# CortexM33 register map
CPU: CM33 r1p0, little endian, MPU, FPU, DSP, VTOR, 4 interrupt priority bits, 52 interrupts, 8 SAU regions
Registers are read-write, reset 0x0 unless marked. A register's access mark holds for its fields unless they carry their own. Offsets are from the block's base; [hi:lo] are bit positions; lines under a group give offsets from that group; {n}, {i} and the like mark numbered series; 'fields as' and 'values as' point back to an identical list.

## PPB (part 2 of 2) — TEAL registers accessible through the debug interface
Base 0xE0000000
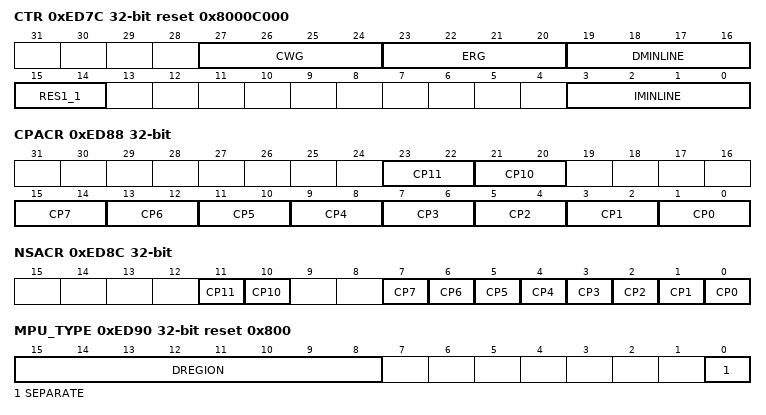
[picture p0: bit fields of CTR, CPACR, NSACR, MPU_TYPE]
0xED7C CTR ro reset 0x8000C000 — Provides information about the architecture of the caches. CTR is RES0 if CLIDR is zero.
  [27:24] CWG — Log2 of the number of words of the maximum size of memory that can be overwritten as a result of the eviction of a cache entry that has had a memory location in it modified
  [23:20] ERG — Log2 of the number of words of the maximum size of the reservation granule that has been implemented for the Load-Exclusive and Store-Exclusive instructions
  [19:16] DMINLINE — Log2 of the number of words in the smallest cache line of all the data caches and unified caches that are controlled by the PE
  [15:14] RES1_1 — Reserved, RES1
  [3:0] IMINLINE — Log2 of the number of words in the smallest cache line of all the instruction caches that are controlled by the PE
0xED88 CPACR — Specifies the access privileges for coprocessors and the FP Extension
  [23:22] CP11 — The value in this field is ignored. If the implementation does not include the FP Extension, this field is RAZ/WI. If the value of this bit is not programmed to the same value as the CP10 field, then the value is UNKNOWN
  [21:20] CP10 — Defines the access rights for the floating-point functionality
  [2n+1:2n] CP{n} (n=0..7) — Controls access privileges for coprocessor {n}
0xED8C NSACR — Defines the Non-secure access permissions for both the FP Extension and coprocessors CP0 to CP7
  [11] CP11 — Enables Non-secure access to the Floating-point Extension
  [10] CP10 — Enables Non-secure access to the Floating-point Extension
  [n] CP{n} (n=0..7) — Enables Non-secure access to coprocessor CP{n}
0xED90 MPU_TYPE ro reset 0x800 — The MPU Type Register indicates how many regions the MPU `FTSSS supports
  [15:8] DREGION — Number of regions supported by the MPU
  [0] SEPARATE — Indicates support for separate instructions and data address regions
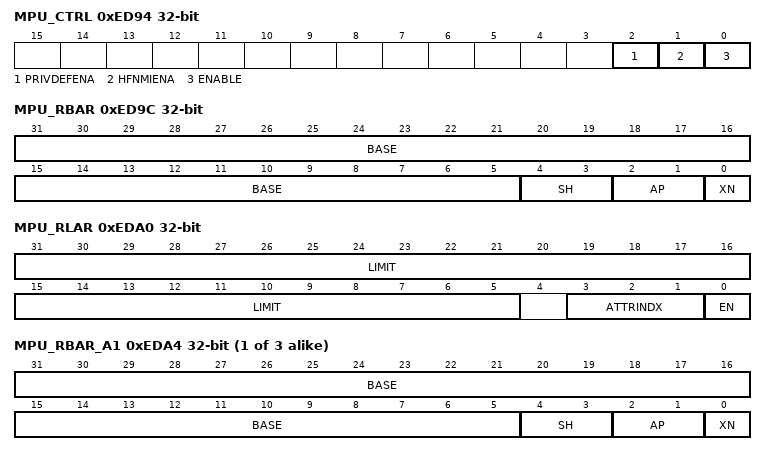
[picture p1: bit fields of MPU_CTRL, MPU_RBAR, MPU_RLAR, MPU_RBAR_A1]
0xED94 MPU_CTRL — Enables the MPU and, when the MPU is enabled, controls whether the default memory map is enabled as a background region for privileged accesses, and whether the MPU is enabled for HardFaults, NMIs, and exception handlers when FAULTMASK is set to 1
  [2] PRIVDEFENA — Controls whether the default memory map is enabled for privileged software
  [1] HFNMIENA — Controls whether handlers executing with priority less than 0 access memory with the MPU enabled or disabled. This applies to HardFaults, NMIs, and exception handlers when FAULTMASK is set to 1
  [0] ENABLE — Enables the MPU
0xED98 MPU_RNR — Selects the region currently accessed by MPU_RBAR and MPU_RLAR
  [2:0] REGION — Indicates the memory region accessed by MPU_RBAR and MPU_RLAR
0xED9C MPU_RBAR — Provides indirect read and write access to the base address of the currently selected MPU region `FTSSS
  [31:5] BASE — Contains bits [31:5] of the lower inclusive limit of the selected MPU memory region. This value is zero extended to provide the base address to be checked against
  [4:3] SH — Defines the Shareability domain of this region for Normal memory
  [2:1] AP — Defines the access permissions for this region
  [0] XN — Defines whether code can be executed from this region
0xEDA0 MPU_RLAR — Provides indirect read and write access to the limit address of the currently selected MPU region `FTSSS
  [31:5] LIMIT — Contains bits [31:5] of the upper inclusive limit of the selected MPU memory region. This value is postfixed with 0x1F to provide the limit address to be checked against
  [3:1] ATTRINDX — Associates a set of attributes in the MPU_MAIR0 and MPU_MAIR1 fields
  [0] EN — Region enable
{0xED9C+8i} MPU_RBAR_A{i} (i=1..3) — Provides indirect read and write access to the base address of the MPU region selected by MPU_RNR[7:2]:({i}[1:0]) `FTSSS
  fields as MPU_RBAR
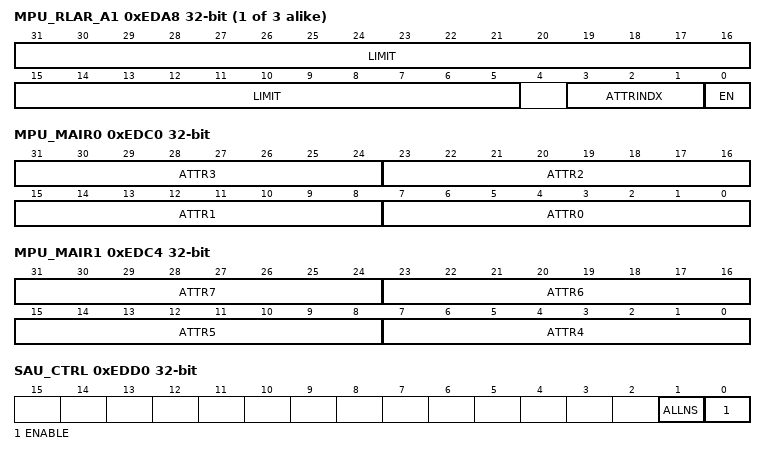
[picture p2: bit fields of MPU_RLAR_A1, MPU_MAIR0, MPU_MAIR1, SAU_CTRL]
{0xEDA0+8i} MPU_RLAR_A{i} (i=1..3) — Provides indirect read and write access to the limit address of the currently selected MPU region selected by MPU_RNR[7:2]:({i}[1:0]) `FTSSS
  fields as MPU_RLAR
0xEDC0 MPU_MAIR0 — Along with MPU_MAIR1, provides the memory attribute encodings corresponding to the AttrIndex values
  [8n+7:8n] ATTR{n} (n=0..3) — Memory attribute encoding for MPU regions with an AttrIndex of {n}
0xEDC4 MPU_MAIR1 — Along with MPU_MAIR0, provides the memory attribute encodings corresponding to the AttrIndex values
  [8n-25:8n-32] ATTR{n} (n=4..7) — Memory attribute encoding for MPU regions with an AttrIndex of {n}
0xEDD0 SAU_CTRL — Allows enabling of the Security Attribution Unit
  [1] ALLNS — When SAU_CTRL.ENABLE is 0 this bit controls if the memory is marked as Non-secure or Secure
  [0] ENABLE — Enables the SAU
0xEDD4 SAU_TYPE ro reset 0x8 — Indicates the number of regions implemented by the Security Attribution Unit
  [7:0] SREGION — The number of implemented SAU regions
0xEDD8 SAU_RNR — Selects the region currently accessed by SAU_RBAR and SAU_RLAR
  [7:0] REGION — Indicates the SAU region accessed by SAU_RBAR and SAU_RLAR
0xEDDC SAU_RBAR — Provides indirect read and write access to the base address of the currently selected SAU region
  [31:5] BADDR — Holds bits [31:5] of the base address for the selected SAU region
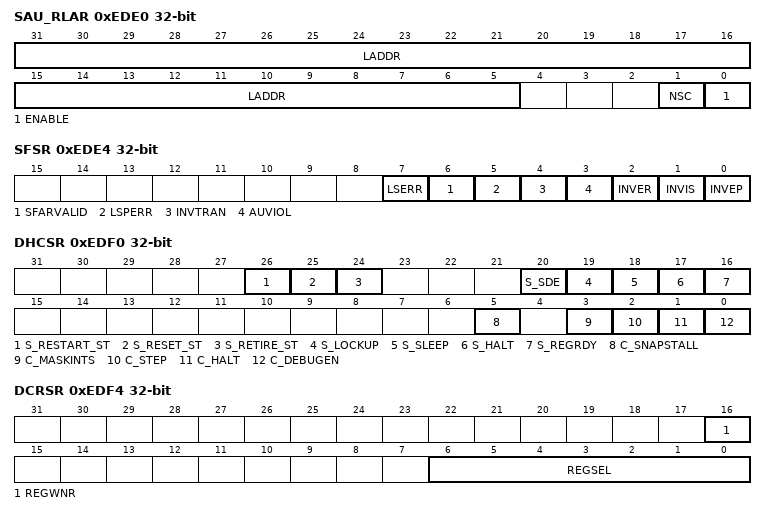
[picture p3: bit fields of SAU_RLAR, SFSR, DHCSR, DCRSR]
0xEDE0 SAU_RLAR — Provides indirect read and write access to the limit address of the currently selected SAU region
  [31:5] LADDR — Holds bits [31:5] of the limit address for the selected SAU region
  [1] NSC — Controls whether Non-secure state is permitted to execute an SG instruction from this region
  [0] ENABLE — SAU region enable
0xEDE4 SFSR — Provides information about any security related faults
  [7] LSERR — Sticky flag indicating that an error occurred during lazy state activation or deactivation
  [6] SFARVALID — This bit is set when the SFAR register contains a valid value. As with similar fields, such as BFSR.BFARVALID and MMFSR.MMARVALID, this bit can be cleared by other exceptions, such as BusFault
  [5] LSPERR — Stick flag indicating that an SAU or IDAU violation occurred during the lazy preservation of floating-point state
  [4] INVTRAN — Sticky flag indicating that an exception was raised due to a branch that was not flagged as being domain crossing causing a transition from Secure to Non-secure memory
  [3] AUVIOL — Sticky flag indicating that an attempt was made to access parts of the address space that are marked as Secure with NS-Req for the transaction set to Non-secure. This bit is not set if the violation occurred during lazy state preservation. See LSPERR
  [2] INVER — This can be caused by EXC_RETURN.DCRS being set to 0 when returning from an exception in the Non-secure state, or by EXC_RETURN.ES being set to 1 when returning from an exception in the Non-secure state
  [1] INVIS — This bit is set if the integrity signature in an exception stack frame is found to be invalid during the unstacking operation
  [0] INVEP — This bit is set if a function call from the Non-secure state or exception targets a non-SG instruction in the Secure state. This bit is also set if the target address is a SG instruction, but there is no matching SAU/IDAU region with the NSC flag set
0xEDE8 SFAR — Shows the address of the memory location that caused a Security violation
  [31:0] ADDRESS — The address of an access that caused a attribution unit violation. This field is only valid when SFSR.SFARVALID is set. This allows the actual flip flops associated with this register to be shared with other fault address registers. If an implementation chooses to share the storage in this way, care must be taken to not leak Secure address information to the Non-secure state. One way of achieving this is to share the SFAR register with the MMFAR_S register, which is not accessible to the Non-secure state
0xEDF0 DHCSR access per field — Controls halting debug
  [26] S_RESTART_ST ro — Indicates the PE has processed a request to clear DHCSR.C_HALT to 0. That is, either a write to DHCSR that clears DHCSR.C_HALT from 1 to 0, or an External Restart Request
  [25] S_RESET_ST ro — Indicates whether the PE has been reset since the last read of the DHCSR
  [24] S_RETIRE_ST ro — Set to 1 every time the PE retires one of more instructions
  [20] S_SDE ro — Indicates whether Secure invasive debug is allowed
  [19] S_LOCKUP ro — Indicates whether the PE is in Lockup state
  [18] S_SLEEP ro — Indicates whether the PE is sleeping
  [17] S_HALT ro — Indicates whether the PE is in Debug state
  [16] S_REGRDY ro — Handshake flag to transfers through the DCRDR
  [5] C_SNAPSTALL rw — Allow imprecise entry to Debug state
  [3] C_MASKINTS rw — When debug is enabled, the debugger can write to this bit to mask PendSV, SysTick and external configurable interrupts
  [2] C_STEP rw — Enable single instruction step
  [1] C_HALT rw — PE enter Debug state halt request
  [0] C_DEBUGEN rw — Enable Halting debug
0xEDF4 DCRSR — With the DCRDR, provides debug access to the general-purpose registers, special-purpose registers, and the FP extension registers. A write to the DCRSR specifies the register to transfer, whether the transfer is a read or write, and starts the transfer
  [16] REGWNR — Specifies the access type for the transfer
  [6:0] REGSEL — Specifies the general-purpose register, special-purpose register, or FP register to transfer
    {v}=R{v} (v=0..12); 13=SP (stack pointer); 14=LR (link register); 15=DebugReturnAddress; 16=XPSR (R) / EAPSR (W); 17=MSP (main stack pointer, SP_main); 18=MSP (process stack pointer, SP_process); 20=Current state (CONTROL | FAULTMASK | BASEPRI | PRIMASK ); 24=MSP_NS (non-secure main stack pointer); 25=PSP_NS (non-secure process stack pointer); 25=PSP_NS (non-secure process stack pointer); 26=MSP_S (secure main stack pointer); 27=PSP_S (secure process stack pointer); 28=MSPLIM_S (secure main stack limit); 29=PSPLIM_S (secure process stack limit); 30=MSPLIM_NS (non-secure main stack limit); 31=PSPLIM_NS (non-secure process stack limit); 33=FPSCR; 34=Secure state (CONTROL_S | FAULTMASK_S | BASEPRI_S | PRIMASK_S); 35=Non-secure state (CONTROL_NS | FAULTMASK_NS | BASEPRI_NS | PRIMASK_NS); 36=VPR; {v}=S{v-64} (FP register) (v=64..95)
0xEDF8 DCRDR — With the DCRSR, provides debug access to the general-purpose registers, special-purpose registers, and the FP Extension registers. If the Main Extension is implemented, it can also be used for message passing between an external debugger and a debug agent running on the PE
  [31:0] DBGTMP — Provides debug access for reading and writing the general-purpose registers, special-purpose registers, and Floating-point Extension registers
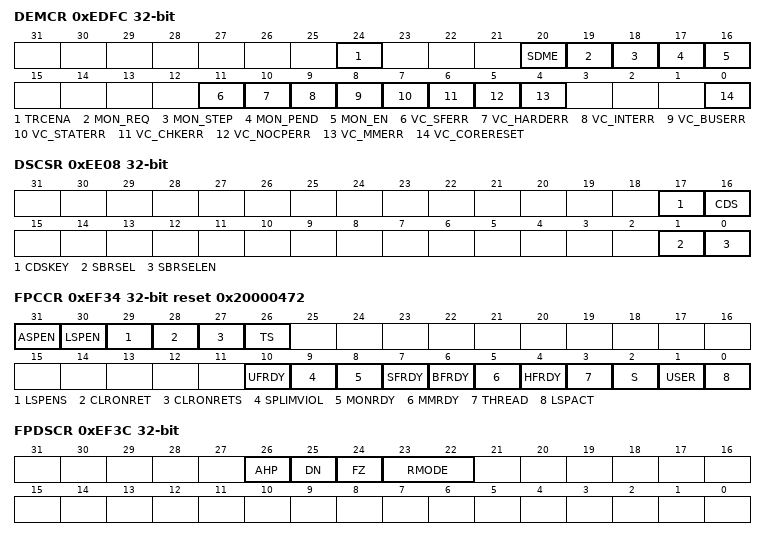
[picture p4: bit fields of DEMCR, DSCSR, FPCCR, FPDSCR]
0xEDFC DEMCR access per field — Manages vector catch behavior and DebugMonitor handling when debugging
  [24] TRCENA rw — Global enable for all DWT and ITM features
  [20] SDME ro — Indicates whether the DebugMonitor targets the Secure or the Non-secure state and whether debug events are allowed in Secure state
  [19] MON_REQ rw — DebugMonitor semaphore bit
  [18] MON_STEP rw — Enable DebugMonitor stepping
  [17] MON_PEND rw — Sets or clears the pending state of the DebugMonitor exception
  [16] MON_EN rw — Enable the DebugMonitor exception
  [11] VC_SFERR rw — SecureFault exception halting debug vector catch enable
  [10] VC_HARDERR rw — HardFault exception halting debug vector catch enable
  [9] VC_INTERR rw — Enable halting debug vector catch for faults during exception entry and return
  [8] VC_BUSERR rw — BusFault exception halting debug vector catch enable
  [7] VC_STATERR rw — Enable halting debug trap on a UsageFault exception caused by a state information error, for example an Undefined Instruction exception
  [6] VC_CHKERR rw — Enable halting debug trap on a UsageFault exception caused by a checking error, for example an alignment check error
  [5] VC_NOCPERR rw — Enable halting debug trap on a UsageFault caused by an access to a coprocessor
  [4] VC_MMERR rw — Enable halting debug trap on a MemManage exception
  [0] VC_CORERESET rw — Enable Reset Vector Catch. This causes a warm reset to halt a running system
0xEE08 DSCSR — Provides control and status information for Secure debug
  [17] CDSKEY — Writes to the CDS bit are ignored unless CDSKEY is concurrently written to zero
  [16] CDS — This field indicates the current Security state of the processor
  [1] SBRSEL — If SBRSELEN is 1 this bit selects whether the Non-secure or the Secure version of the memory-mapped Banked registers are accessible to the debugger
  [0] SBRSELEN — Controls whether the SBRSEL field or the current Security state of the processor selects which version of the memory-mapped Banked registers are accessed to the debugger
0xEF00 STIR — Provides a mechanism for software to generate an interrupt
  [8:0] INTID — Indicates the interrupt to be pended. The value written is (ExceptionNumber - 16)
0xEF34 FPCCR reset 0x20000472 — Holds control data for the Floating-point extension
  [31] ASPEN — When this bit is set to 1, execution of a floating-point instruction sets the CONTROL.FPCA bit to 1
  [30] LSPEN — Enables lazy context save of floating-point state
  [29] LSPENS — This bit controls whether the LSPEN bit is writeable from the Non-secure state
  [28] CLRONRET — Clear floating-point caller saved registers on exception return
  [27] CLRONRETS — This bit controls whether the CLRONRET bit is writeable from the Non-secure state
  [26] TS — Treat floating-point registers as Secure enable
  [10] UFRDY — Indicates whether the software executing when the PE allocated the floating-point stack frame was able to set the UsageFault exception to pending
  [9] SPLIMVIOL — This bit is banked between the Security states and indicates whether the floating-point context violates the stack pointer limit that was active when lazy state preservation was activated. SPLIMVIOL modifies the lazy floating-point state preservation behavior
  [8] MONRDY — Indicates whether the software executing when the PE allocated the floating-point stack frame was able to set the DebugMonitor exception to pending
  [7] SFRDY — Indicates whether the software executing when the PE allocated the floating-point stack frame was able to set the SecureFault exception to pending. This bit is only present in the Secure version of the register, and behaves as RAZ/WI when accessed from the Non-secure state
  [6] BFRDY — Indicates whether the software executing when the PE allocated the floating-point stack frame was able to set the BusFault exception to pending
  [5] MMRDY — Indicates whether the software executing when the PE allocated the floating-point stack frame was able to set the MemManage exception to pending
  [4] HFRDY — Indicates whether the software executing when the PE allocated the floating-point stack frame was able to set the HardFault exception to pending
  [3] THREAD — Indicates the PE mode when it allocated the floating-point stack frame
  [2] S — Security status of the floating-point context. This bit is only present in the Secure version of the register, and behaves as RAZ/WI when accessed from the Non-secure state. This bit is updated whenever lazy state preservation is activated, or when a floating-point instruction is executed
  [1] USER — Indicates the privilege level of the software executing when the PE allocated the floating-point stack frame
  [0] LSPACT — Indicates whether lazy preservation of the floating-point state is active
0xEF38 FPCAR — Holds the location of the unpopulated floating-point register space allocated on an exception stack frame
  [31:3] ADDRESS — The location of the unpopulated floating-point register space allocated on an exception stack frame
0xEF3C FPDSCR — Holds the default values for the floating-point status control data that the PE assigns to the FPSCR when it creates a new floating-point context
  [26] AHP — Default value for FPSCR.AHP
  [25] DN — Default value for FPSCR.DN
  [24] FZ — Default value for FPSCR.FZ
  [23:22] RMODE — Default value for FPSCR.RMode
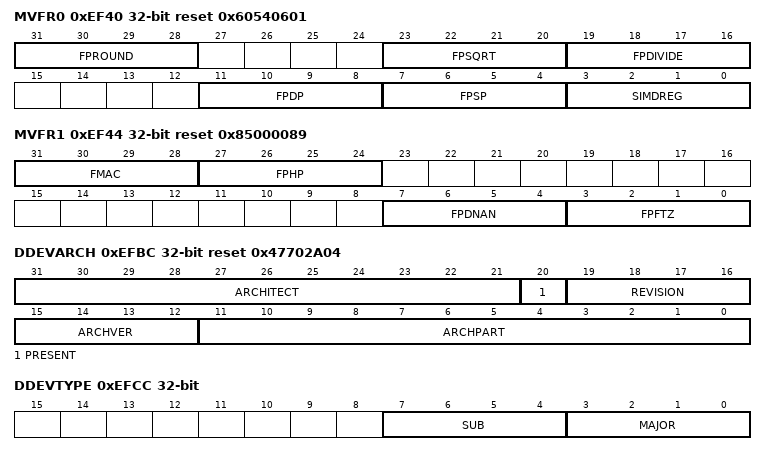
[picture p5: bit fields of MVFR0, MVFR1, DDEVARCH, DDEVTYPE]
0xEF40 MVFR0 ro reset 0x60540601 — Describes the features provided by the Floating-point Extension
  [31:28] FPROUND — Indicates the rounding modes supported by the FP Extension
  [23:20] FPSQRT — Indicates the support for FP square root operations
  [19:16] FPDIVIDE — Indicates the support for FP divide operations
  [11:8] FPDP — Indicates support for FP double-precision operations
  [7:4] FPSP — Indicates support for FP single-precision operations
  [3:0] SIMDREG — Indicates size of FP register file
0xEF44 MVFR1 ro reset 0x85000089 — Describes the features provided by the Floating-point Extension
  [31:28] FMAC — Indicates whether the FP Extension implements the fused multiply accumulate instructions
  [27:24] FPHP — Indicates whether the FP Extension implements half-precision FP conversion instructions
  [7:4] FPDNAN — Indicates whether the FP hardware implementation supports NaN propagation
  [3:0] FPFTZ — Indicates whether subnormals are always flushed-to-zero
0xEF48 MVFR2 ro reset 0x60 — Describes the features provided by the Floating-point Extension
  [7:4] FPMISC — Indicates support for miscellaneous FP features
0xEFBC DDEVARCH ro reset 0x47702A04 — Provides CoreSight discovery information for the SCS
  [31:21] ARCHITECT — Defines the architect of the component. Bits [31:28] are the JEP106 continuation code (JEP106 bank ID, minus 1) and bits [27:21] are the JEP106 ID code.
  [20] PRESENT — Defines that the DEVARCH register is present
  [19:16] REVISION — Defines the architecture revision of the component
  [15:12] ARCHVER — Defines the architecture version of the component
  [11:0] ARCHPART — Defines the architecture of the component
0xEFCC DDEVTYPE ro — Provides CoreSight discovery information for the SCS
  [7:4] SUB — Component sub-type
  [3:0] MAJOR — CoreSight major type
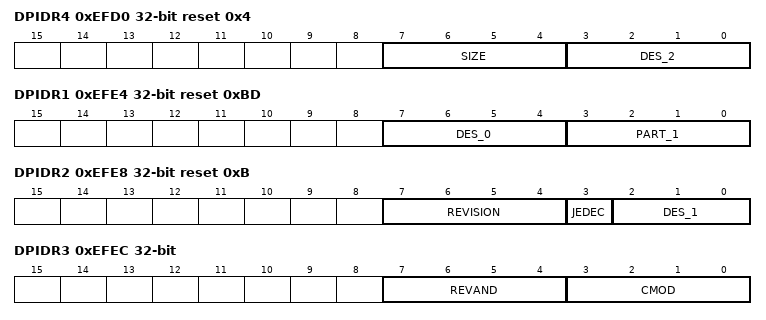
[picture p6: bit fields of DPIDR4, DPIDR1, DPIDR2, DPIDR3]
0xEFD0 DPIDR4 ro reset 0x4 — Provides CoreSight discovery information for the SCS
  [7:4] SIZE — See CoreSight Architecture Specification
  [3:0] DES_2 — See CoreSight Architecture Specification
{0xEFC0+4i} DPIDR{i} (i=5..7) — Provides CoreSight discovery information for the SCS
  [31:0] DPIDR{i}
0xEFE0 DPIDR0 ro reset 0x21 — Provides CoreSight discovery information for the SCS
  [7:0] PART_0 — See CoreSight Architecture Specification
0xEFE4 DPIDR1 ro reset 0xBD — Provides CoreSight discovery information for the SCS
  [7:4] DES_0 — See CoreSight Architecture Specification
  [3:0] PART_1 — See CoreSight Architecture Specification
0xEFE8 DPIDR2 ro reset 0xB — Provides CoreSight discovery information for the SCS
  [7:4] REVISION — See CoreSight Architecture Specification
  [3] JEDEC — See CoreSight Architecture Specification
  [2:0] DES_1 — See CoreSight Architecture Specification
0xEFEC DPIDR3 ro — Provides CoreSight discovery information for the SCS
  [7:4] REVAND — See CoreSight Architecture Specification
  [3:0] CMOD — See CoreSight Architecture Specification
0xEFF0 DCIDR0 ro reset 0xD — Provides CoreSight discovery information for the SCS
  [7:0] PRMBL_0 — See CoreSight Architecture Specification
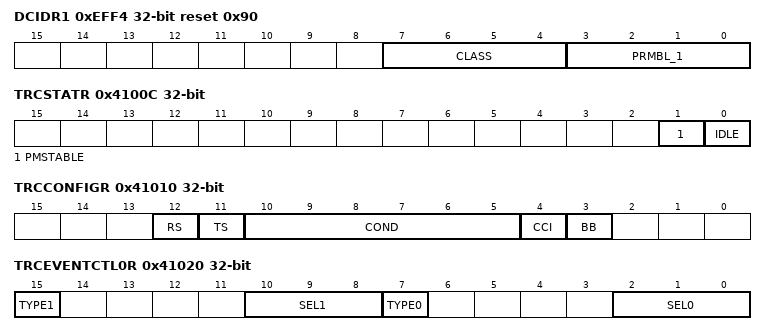
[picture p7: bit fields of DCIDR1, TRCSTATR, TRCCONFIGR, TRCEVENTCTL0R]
0xEFF4 DCIDR1 ro reset 0x90 — Provides CoreSight discovery information for the SCS
  [7:4] CLASS — See CoreSight Architecture Specification
  [3:0] PRMBL_1 — See CoreSight Architecture Specification
0xEFF8 DCIDR2 ro reset 0x5 — Provides CoreSight discovery information for the SCS
  [7:0] PRMBL_2 — See CoreSight Architecture Specification
0xEFFC DCIDR3 ro reset 0xB1 — Provides CoreSight discovery information for the SCS
  [7:0] PRMBL_3 — See CoreSight Architecture Specification
0x41004 TRCPRGCTLR — Programming Control Register
  [0] EN — Trace Unit Enable
0x4100C TRCSTATR ro — The TRCSTATR indicates the ETM-Teal status
  [1] PMSTABLE — Indicates whether the ETM-Teal registers are stable and can be read
  [0] IDLE — Indicates that the trace unit is inactive
0x41010 TRCCONFIGR — The TRCCONFIGR sets the basic tracing options for the trace unit
  [12] RS — Return stack enable
  [11] TS — Global timestamp tracing
  [10:5] COND — Conditional instruction tracing
  [4] CCI — Cycle counting in instruction trace
  [3] BB — Branch broadcast mode
0x41020 TRCEVENTCTL0R — The TRCEVENTCTL0R controls the tracing of events in the trace stream. The events also drive the ETM-Teal external outputs.
  [15] TYPE1 — Selects the resource type for event 1
  [10:8] SEL1 — Selects the resource number, based on the value of TYPE1: When TYPE1 is 0, selects a single selected resource from 0-15 defined by SEL1[2:0]. When TYPE1 is 1, selects a Boolean combined resource pair from 0-7 defined by SEL1[2:0]
  [7] TYPE0 — Selects the resource type for event 0
  [2:0] SEL0 — Selects the resource number, based on the value of TYPE0: When TYPE1 is 0, selects a single selected resource from 0-15 defined by SEL0[2:0]. When TYPE1 is 1, selects a Boolean combined resource pair from 0-7 defined by SEL0[2:0]
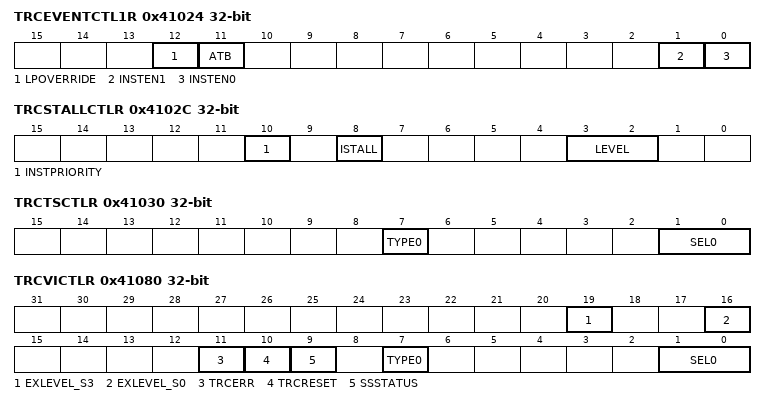
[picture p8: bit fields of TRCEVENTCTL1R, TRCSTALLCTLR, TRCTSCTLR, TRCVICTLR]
0x41024 TRCEVENTCTL1R — The TRCEVENTCTL1R controls how the events selected by TRCEVENTCTL0R behave
  [12] LPOVERRIDE — Low power state behavior override
  [11] ATB — ATB enabled
  [1] INSTEN1 — One bit per event, to enable generation of an event element in the instruction trace stream when the selected event occurs
  [0] INSTEN0 — One bit per event, to enable generation of an event element in the instruction trace stream when the selected event occurs
0x4102C TRCSTALLCTLR access per field — The TRCSTALLCTLR enables ETM-Teal to stall the processor if the ETM-Teal FIFO goes over the programmed level to minimize risk of overflow
  [10] INSTPRIORITY ro — Reserved, RES0
  [8] ISTALL rw — Stall processor based on instruction trace buffer space
  [3:2] LEVEL rw — Threshold at which stalling becomes active. This provides four levels. This level can be varied to optimize the level of invasion caused by stalling, balanced against the risk of a FIFO overflow
0x41030 TRCTSCTLR — The TRCTSCTLR controls the insertion of global timestamps into the trace stream. A timestamp is always inserted into the instruction trace stream
  [7] TYPE0 — Selects the resource type for event 0
  [1:0] SEL0 — Selects the resource number, based on the value of TYPE0: When TYPE1 is 0, selects a single selected resource from 0-15 defined by SEL0[2:0]. When TYPE1 is 1, selects a Boolean combined resource pair from 0-7 defined by SEL0[2:0]
0x41034 TRCSYNCPR ro reset 0xA — The TRCSYNCPR specifies the period of trace synchronization of the trace streams. TRCSYNCPR defines a number of bytes of trace between requests for trace synchronization. This value is always a power of two
  [4:0] PERIOD — Defines the number of bytes of trace between trace synchronization requests as a total of the number of bytes generated by the instruction stream. The number of bytes is 2N where N is the value of this field: - A value of zero disables these periodic trace synchronization requests, but does not disable other trace synchronization requests. - The minimum value that can be programmed, other than zero, is 8, providing a minimum trace synchronization period of 256 bytes. - The maximum value is 20, providing a maximum trace synchronization period of 2^20 bytes
0x41038 TRCCCCTLR — The TRCCCCTLR sets the threshold value for instruction trace cycle counting. The threshold represents the minimum interval between cycle count trace packets
  [11:0] THRESHOLD — Instruction trace cycle count threshold
0x41080 TRCVICTLR — The TRCVICTLR controls instruction trace filtering
  [19] EXLEVEL_S3 — In Secure state, each bit controls whether instruction tracing is enabled for the corresponding exception level
  [16] EXLEVEL_S0 — In Secure state, each bit controls whether instruction tracing is enabled for the corresponding exception level
  [11] TRCERR — Selects whether a system error exception must always be traced
  [10] TRCRESET — Selects whether a reset exception must always be traced
  [9] SSSTATUS — Indicates the current status of the start/stop logic
  [7] TYPE0 — Selects the resource type for event 0
  [1:0] SEL0 — Selects the resource number, based on the value of TYPE0: When TYPE1 is 0, selects a single selected resource from 0-15 defined by SEL0[2:0]. When TYPE1 is 1, selects a Boolean combined resource pair from 0-7 defined by SEL0[2:0]
0x41140 TRCCNTRLDVR0 — The TRCCNTRLDVR defines the reload value for the reduced function counter
  [15:0] VALUE — Defines the reload value for the counter. This value is loaded into the counter each time the reload event occurs
0x41180 TRCIDR8 ro
  [31:0] MAXSPEC — reads as `ImpDef
0x41184 TRCIDR9 ro
  [31:0] NUMP0KEY — reads as `ImpDef
0x41188 TRCIDR10 ro
  [31:0] NUMP1KEY — reads as `ImpDef
0x4118C TRCIDR11 ro
  [31:0] NUMP1SPC — reads as `ImpDef
0x41190 TRCIDR12 ro reset 0x1
  [31:0] NUMCONDKEY — reads as `ImpDef
0x41194 TRCIDR13 ro
  [31:0] NUMCONDSPC — reads as `ImpDef
0x411C0 TRCIMSPEC ro — The TRCIMSPEC shows the presence of any IMPLEMENTATION SPECIFIC features, and enables any features that are provided
  [3:0] SUPPORT — Reserved, RES0
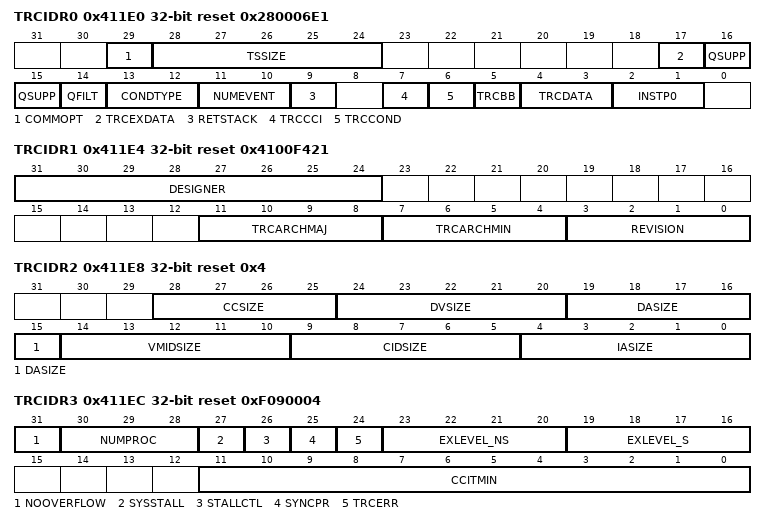
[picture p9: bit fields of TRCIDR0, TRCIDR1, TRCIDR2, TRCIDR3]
0x411E0 TRCIDR0 ro reset 0x280006E1
  [29] COMMOPT — reads as `ImpDef
  [28:24] TSSIZE — reads as `ImpDef
  [17] TRCEXDATA — reads as `ImpDef
  [16:15] QSUPP — reads as `ImpDef
  [14] QFILT — reads as `ImpDef
  [13:12] CONDTYPE — reads as `ImpDef
  [11:10] NUMEVENT — reads as `ImpDef
  [9] RETSTACK — reads as `ImpDef
  [7] TRCCCI — reads as `ImpDef
  [6] TRCCOND — reads as `ImpDef
  [5] TRCBB — reads as `ImpDef
  [4:3] TRCDATA — reads as `ImpDef
  [2:1] INSTP0 — reads as `ImpDef
0x411E4 TRCIDR1 ro reset 0x4100F421
  [31:24] DESIGNER — reads as `ImpDef
  [11:8] TRCARCHMAJ — reads as 0b0100
  [7:4] TRCARCHMIN — reads as 0b0000
  [3:0] REVISION — reads as `ImpDef
0x411E8 TRCIDR2 ro reset 0x4
  [28:25] CCSIZE — reads as `ImpDef
  [24:20] DVSIZE — reads as `ImpDef
  [19:15] DASIZE — reads as `ImpDef
  [14:10] VMIDSIZE — reads as `ImpDef
  [9:5] CIDSIZE — reads as `ImpDef
  [4:0] IASIZE — reads as `ImpDef
0x411EC TRCIDR3 ro reset 0xF090004
  [31] NOOVERFLOW — reads as `ImpDef
  [30:28] NUMPROC — reads as `ImpDef
  [27] SYSSTALL — reads as `ImpDef
  [26] STALLCTL — reads as `ImpDef
  [25] SYNCPR — reads as `ImpDef
  [24] TRCERR — reads as `ImpDef
  [23:20] EXLEVEL_NS — reads as `ImpDef
  [19:16] EXLEVEL_S — reads as `ImpDef
  [11:0] CCITMIN — reads as `ImpDef
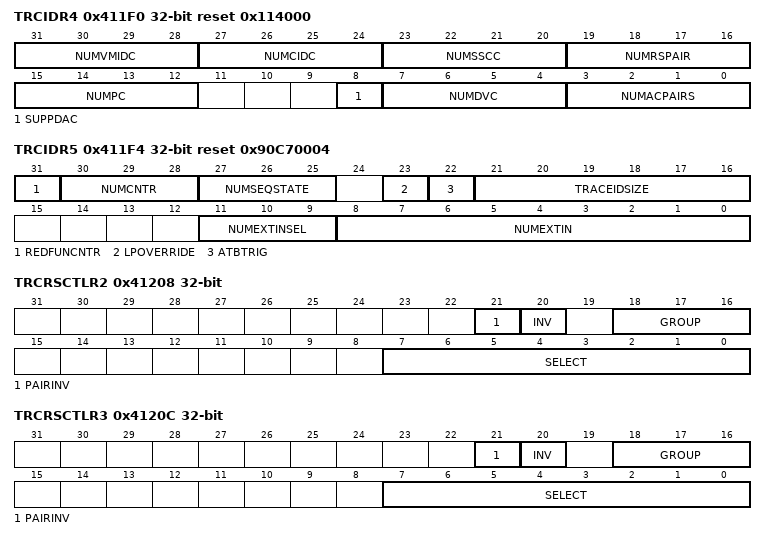
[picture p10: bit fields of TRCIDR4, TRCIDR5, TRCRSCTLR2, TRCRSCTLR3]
0x411F0 TRCIDR4 ro reset 0x114000
  [31:28] NUMVMIDC — reads as `ImpDef
  [27:24] NUMCIDC — reads as `ImpDef
  [23:20] NUMSSCC — reads as `ImpDef
  [19:16] NUMRSPAIR — reads as `ImpDef
  [15:12] NUMPC — reads as `ImpDef
  [8] SUPPDAC — reads as `ImpDef
  [7:4] NUMDVC — reads as `ImpDef
  [3:0] NUMACPAIRS — reads as `ImpDef
0x411F4 TRCIDR5 ro reset 0x90C70004
  [31] REDFUNCNTR — reads as `ImpDef
  [30:28] NUMCNTR — reads as `ImpDef
  [27:25] NUMSEQSTATE — reads as `ImpDef
  [23] LPOVERRIDE — reads as `ImpDef
  [22] ATBTRIG — reads as `ImpDef
  [21:16] TRACEIDSIZE — reads as 0x07
  [11:9] NUMEXTINSEL — reads as `ImpDef
  [8:0] NUMEXTIN — reads as `ImpDef
0x411F8 TRCIDR6
  [31:0] TRCIDR6
0x411FC TRCIDR7
  [31:0] TRCIDR7
0x41208 TRCRSCTLR2 — The TRCRSCTLR controls the trace resources
  [21] PAIRINV — Inverts the result of a combined pair of resources. This bit is only implemented on the lower register for a pair of resource selectors
  [20] INV — Inverts the selected resources
  [18:16] GROUP — Selects a group of resource
  [7:0] SELECT — Selects one or more resources from the wanted group. One bit is provided per resource from the group
0x4120C TRCRSCTLR3 — The TRCRSCTLR controls the trace resources
  fields as TRCRSCTLR2
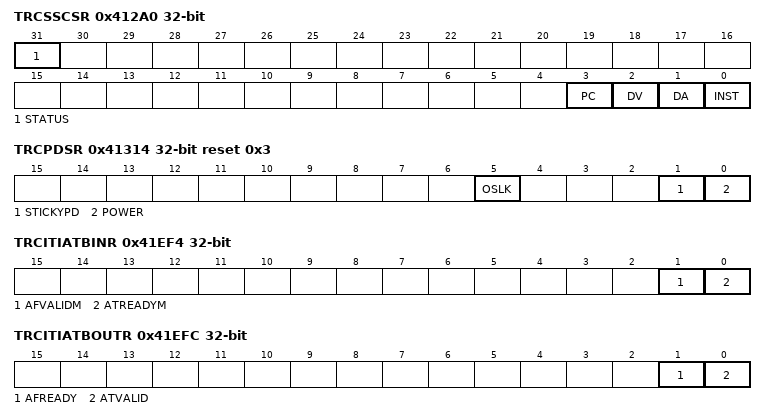
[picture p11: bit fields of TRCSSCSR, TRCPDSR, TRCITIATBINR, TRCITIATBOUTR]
0x412A0 TRCSSCSR access per field — Controls the corresponding single-shot comparator resource
  [31] STATUS rw — Single-shot status bit. Indicates if any of the comparators, that TRCSSCCRn.SAC or TRCSSCCRn.ARC selects, have matched
  [3] PC ro — Reserved, RES1
  [2] DV ro — Reserved, RES0
  [1] DA ro — Reserved, RES0
  [0] INST ro — Reserved, RES0
0x412C0 TRCSSPCICR — Selects the PE comparator inputs for Single-shot control
  [3:0] PC — Selects one or more PE comparator inputs for Single-shot control. TRCIDR4.NUMPC defines the size of the PC field. 1 bit is provided for each implemented PE comparator input. For example, if bit[1] == 1 this selects PE comparator input 1 for Single-shot control
0x41310 TRCPDCR — Requests the system to provide power to the trace unit
  [3] PU — Powerup request bit:
0x41314 TRCPDSR ro reset 0x3 — Returns the following information about the trace unit: - OS Lock status. - Core power domain status. - Power interruption status
  [5] OSLK — OS Lock status bit:
  [1] STICKYPD — Sticky powerdown status bit. Indicates whether the trace register state is valid:
  [0] POWER — Power status bit:
0x41EE4 TRCITATBIDR — Trace Integration ATB Identification Register
  [6:0] ID — Trace ID
0x41EF4 TRCITIATBINR — Trace Integration Instruction ATB In Register
  [1] AFVALIDM — Integration Mode instruction AFVALIDM in
  [0] ATREADYM — Integration Mode instruction ATREADYM in
0x41EFC TRCITIATBOUTR — Trace Integration Instruction ATB Out Register
  [1] AFREADY — Integration Mode instruction AFREADY out
  [0] ATVALID — Integration Mode instruction ATVALID out
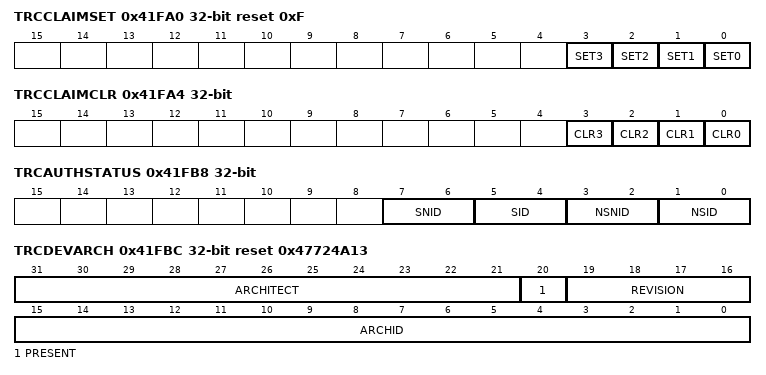
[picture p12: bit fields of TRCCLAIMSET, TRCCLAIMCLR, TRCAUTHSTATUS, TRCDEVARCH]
0x41FA0 TRCCLAIMSET reset 0xF — Claim Tag Set Register
  [n] SET{n} (n=0..3) — When a write to one of these bits occurs, with the value:
0x41FA4 TRCCLAIMCLR — Claim Tag Clear Register
  [n] CLR{n} (n=0..3) — When a write to one of these bits occurs, with the value:
0x41FB8 TRCAUTHSTATUS ro — Returns the level of tracing that the trace unit can support
  [7:6] SNID — Indicates whether the system enables the trace unit to support Secure non-invasive debug:
  [5:4] SID — Indicates whether the trace unit supports Secure invasive debug:
  [3:2] NSNID — Indicates whether the system enables the trace unit to support Non-secure non-invasive debug:
  [1:0] NSID — Indicates whether the trace unit supports Non-secure invasive debug:
0x41FBC TRCDEVARCH ro reset 0x47724A13
  [31:21] ARCHITECT — reads as 0b01000111011
  [20] PRESENT — reads as 0b1
  [19:16] REVISION — reads as 0b0000
  [15:0] ARCHID — reads as 0b0100101000010011
0x41FC8 TRCDEVID
  [31:0] TRCDEVID
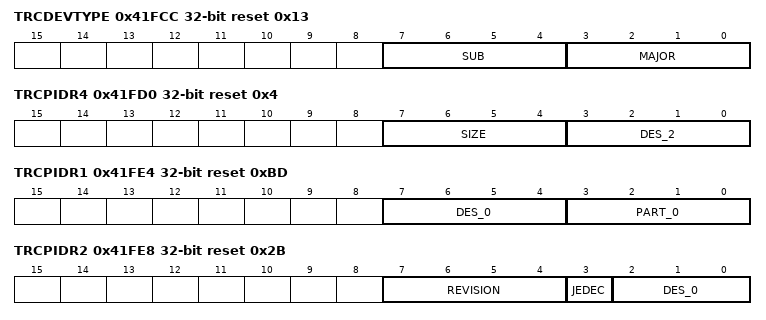
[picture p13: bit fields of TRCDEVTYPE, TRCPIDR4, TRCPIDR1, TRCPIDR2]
0x41FCC TRCDEVTYPE ro reset 0x13
  [7:4] SUB — reads as 0b0001
  [3:0] MAJOR — reads as 0b0011
0x41FD0 TRCPIDR4 ro reset 0x4
  [7:4] SIZE — reads as `ImpDef
  [3:0] DES_2 — reads as `ImpDef
{0x41FC0+4i} TRCPIDR{i} (i=5..7)
  [31:0] TRCPIDR{i}
0x41FE0 TRCPIDR0 ro reset 0x21
  [7:0] PART_0 — reads as `ImpDef
0x41FE4 TRCPIDR1 ro reset 0xBD
  [7:4] DES_0 — reads as `ImpDef
  [3:0] PART_0 — reads as `ImpDef
0x41FE8 TRCPIDR2 ro reset 0x2B
  [7:4] REVISION — reads as `ImpDef
  [3] JEDEC — reads as 0b1
  [2:0] DES_0 — reads as `ImpDef
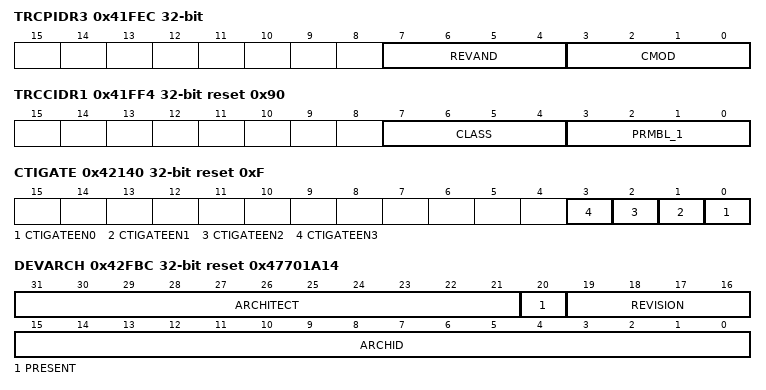
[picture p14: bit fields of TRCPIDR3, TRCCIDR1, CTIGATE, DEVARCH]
0x41FEC TRCPIDR3 ro
  [7:4] REVAND — reads as `ImpDef
  [3:0] CMOD — reads as `ImpDef
0x41FF0 TRCCIDR0 ro reset 0xD
  [7:0] PRMBL_0 — reads as 0b00001101
0x41FF4 TRCCIDR1 ro reset 0x90
  [7:4] CLASS — reads as 0b1001
  [3:0] PRMBL_1 — reads as 0b0000
0x41FF8 TRCCIDR2 ro reset 0x5
  [7:0] PRMBL_2 — reads as 0b00000101
0x41FFC TRCCIDR3 ro reset 0xB1
  [7:0] PRMBL_3 — reads as 0b10110001
0x42000 CTICONTROL
  [0] GLBEN — Enables or disables the CTI
0x42010 CTIINTACK — CTI Interrupt Acknowledge Register
  [7:0] INTACK — Acknowledges the corresponding ctitrigout output. There is one bit of the register for each ctitrigout output. When a 1 is written to a bit in this register, the corresponding ctitrigout is acknowledged, causing it to be cleared.
0x42014 CTIAPPSET — CTI Application Trigger Set Register
  [3:0] APPSET — Setting a bit HIGH generates a channel event for the selected channel. There is one bit of the register for each channel
0x42018 CTIAPPCLEAR — CTI Application Trigger Clear Register
  [3:0] APPCLEAR — Sets the corresponding bits in the CTIAPPSET to 0. There is one bit of the register for each channel.
0x4201C CTIAPPPULSE — CTI Application Pulse Register
  [3:0] APPULSE — Setting a bit HIGH generates a channel event pulse for the selected channel. There is one bit of the register for each channel.
{0x42020+4i} CTIINEN{i} (i=0..7) — CTI Trigger to Channel Enable Registers
  [3:0] TRIGINEN — Enables a cross trigger event to the corresponding channel when a ctitrigin input is activated. There is one bit of the field for each of the four channels
{0x420A0+4i} CTIOUTEN{i} (i=0..7) — CTI Trigger to Channel Enable Registers
  [3:0] TRIGOUTEN — Enables a cross trigger event to ctitrigout when the corresponding channel is activated. There is one bit of the field for each of the four channels.
0x42130 CTITRIGINSTATUS ro — CTI Trigger to Channel Enable Registers
  [7:0] TRIGINSTATUS — Shows the status of the ctitrigin inputs. There is one bit of the field for each trigger input.Because the register provides a view of the raw ctitrigin inputs, the reset value is UNKNOWN.
0x42134 CTITRIGOUTSTATUS ro — CTI Trigger In Status Register
  [7:0] TRIGOUTSTATUS — Shows the status of the ctitrigout outputs. There is one bit of the field for each trigger output.
0x42138 CTICHINSTATUS ro — CTI Channel In Status Register
  [3:0] CTICHOUTSTATUS — Shows the status of the ctichout outputs. There is one bit of the field for each channel output
0x42140 CTIGATE reset 0xF — Enable CTI Channel Gate register
  [n] CTIGATEEN{n} (n=0..3) — Enable ctichout{n}. Set to 0 to disable channel propagation.
0x42144 ASICCTL — External Multiplexer Control register
  [31:0] ASICCTL
0x42EE4 ITCHOUT — Integration Test Channel Output register
  [3:0] CTCHOUT — Sets the value of the ctichout outputs
0x42EE8 ITTRIGOUT — Integration Test Trigger Output register
  [7:0] CTTRIGOUT — Sets the value of the ctitrigout outputs
0x42EF4 ITCHIN ro — Integration Test Channel Input register
  [3:0] CTCHIN — Reads the value of the ctichin inputs.
0x42F00 ITCTRL — Integration Mode Control register
  [0] IME — Integration Mode Enable
0x42FBC DEVARCH ro reset 0x47701A14 — Device Architecture register
  [31:21] ARCHITECT — Indicates the component architect
  [20] PRESENT — Indicates whether the DEVARCH register is present
  [19:16] REVISION — Indicates the architecture revision
  [15:0] ARCHID — Indicates the component
0x42FC8 DEVID ro reset 0x40800 — Device Configuration register
  [19:16] NUMCH — Number of ECT channels available
  [15:8] NUMTRIG — Number of ECT triggers available.
  [4:0] EXTMUXNUM — Indicates the number of multiplexers available on Trigger Inputs and Trigger Outputs that are using asicctl. The default value of 0b00000 indicates that no multiplexing is present. This value of this bit depends on the Verilog define EXTMUXNUM that you must change accordingly.
0x42FCC DEVTYPE ro reset 0x14 — Device Type Identifier register
  [7:4] SUB — Sub-classification of the type of the debug component as specified in the ARM Architecture Specification within the major classification as specified in the MAJOR field.
  [3:0] MAJOR — Major classification of the type of the debug component as specified in the ARM Architecture Specification for this debug and trace component.
0x42FD0 PIDR4 ro reset 0x4 — CoreSight Peripheral ID4
  [7:4] SIZE — Always 0b0000. Indicates that the device only occupies 4KB of memory
  [3:0] DES_2 — Together, PIDR1.DES_0, PIDR2.DES_1, and PIDR4.DES_2 identify the designer of the component.
{0x42FC0+4i} PIDR{i} (i=5..7) — CoreSight Peripheral ID{i}
  [31:0] PIDR{i}
0x42FE0 PIDR0 ro reset 0x21 — CoreSight Peripheral ID0
  [7:0] PART_0 — Bits[7:0] of the 12-bit part number of the component. The designer of the component assigns this part number.
0x42FE4 PIDR1 ro reset 0xBD — CoreSight Peripheral ID1
  [7:4] DES_0 — Together, PIDR1.DES_0, PIDR2.DES_1, and PIDR4.DES_2 identify the designer of the component.
  [3:0] PART_1 — Bits[11:8] of the 12-bit part number of the component. The designer of the component assigns this part number.
0x42FE8 PIDR2 ro reset 0xB — CoreSight Peripheral ID2
  [7:4] REVISION — This device is at r1p0
  [3] JEDEC — Always 1. Indicates that the JEDEC-assigned designer ID is used.
  [2:0] DES_1 — Together, PIDR1.DES_0, PIDR2.DES_1, and PIDR4.DES_2 identify the designer of the component.
0x42FEC PIDR3 ro — CoreSight Peripheral ID3
  [7:4] REVAND — Indicates minor errata fixes specific to the revision of the component being used, for example metal fixes after implementation. In most cases, this field is 0b0000. ARM recommends that the component designers ensure that a metal fix can change this field if required, for example, by driving it from registers that reset to 0b0000.
  [3:0] CMOD — Customer Modified. Indicates whether the customer has modified the behavior of the component. In most cases, this field is 0b0000. Customers change this value when they make authorized modifications to this component.
0x42FF0 CIDR0 ro reset 0xD — CoreSight Component ID0
  [7:0] PRMBL_0 — Preamble[0]. Contains bits[7:0] of the component identification code
0x42FF4 CIDR1 ro reset 0x90 — CoreSight Component ID1
  [7:4] CLASS — Class of the component, for example, whether the component is a ROM table or a generic CoreSight component. Contains bits[15:12] of the component identification code.
  [3:0] PRMBL_1 — Preamble[1]. Contains bits[11:8] of the component identification code.
0x42FF8 CIDR2 ro reset 0x5 — CoreSight Component ID2
  [7:0] PRMBL_2 — Preamble[2]. Contains bits[23:16] of the component identification code.
0x42FFC CIDR3 ro reset 0xB1 — CoreSight Component ID3
  [7:0] PRMBL_3 — Preamble[3]. Contains bits[31:24] of the component identification code.
